# STM32U5A9 register map
File version: 1.7
CPU: CM33 r0p1, little endian, MPU, FPU, 4 interrupt priority bits
Registers are 32-bit, read-write, reset 0x0 unless marked. A register's access mark holds for its fields unless they carry their own. Offsets are from the block's base; [hi:lo] are bit positions; {n}, {i} and the like mark numbered series.

## DCMI — Digital camera interface
Base 0x4202C000
Same registers: SEC_DCMI 0x5202C000
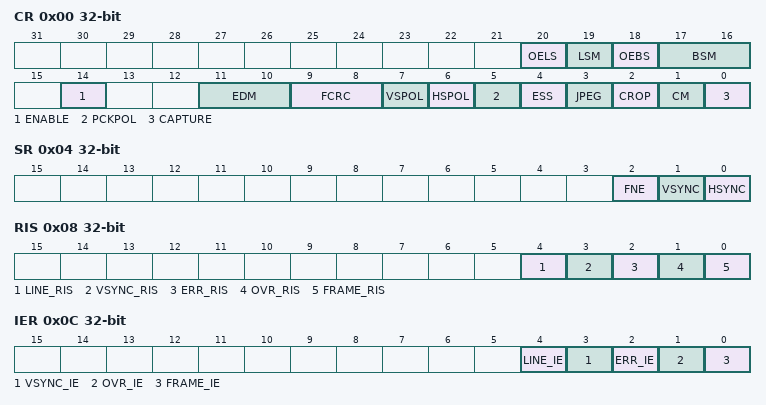
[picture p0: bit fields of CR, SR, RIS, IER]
0x00 CR — control register
  [20] OELS — Odd/Even Line Select (Line Select Start)
  [19] LSM — Line Select mode
  [18] OEBS — Odd/Even Byte Select (Byte Select Start)
  [17:16] BSM — Byte Select mode
  [14] ENABLE — DCMI enable
  [11:10] EDM — Extended data mode
  [9:8] FCRC — Frame capture rate control
  [7] VSPOL — Vertical synchronization polarity
  [6] HSPOL — Horizontal synchronization polarity
  [5] PCKPOL — Pixel clock polarity
  [4] ESS — Embedded synchronization select
  [3] JPEG — JPEG format
  [2] CROP — Crop feature
  [1] CM — Capture mode
  [0] CAPTURE — Capture enable
0x04 SR ro — status register
  [2] FNE — FIFO not empty
  [1] VSYNC — Vertical synchronization
  [0] HSYNC — Horizontal synchronization
0x08 RIS ro — raw interrupt status register
  [4] LINE_RIS — Line raw interrupt status
  [3] VSYNC_RIS — DCMI_VSYNC raw interrupt status
  [2] ERR_RIS — Synchronization error raw interrupt status
  [1] OVR_RIS — Overrun raw interrupt status
  [0] FRAME_RIS — Capture complete raw interrupt status
0x0C IER — interrupt enable register
  [4] LINE_IE — Line interrupt enable
  [3] VSYNC_IE — DCMI_VSYNC interrupt enable
  [2] ERR_IE — Synchronization error interrupt enable
  [1] OVR_IE — Overrun interrupt enable
  [0] FRAME_IE — Capture complete interrupt enable
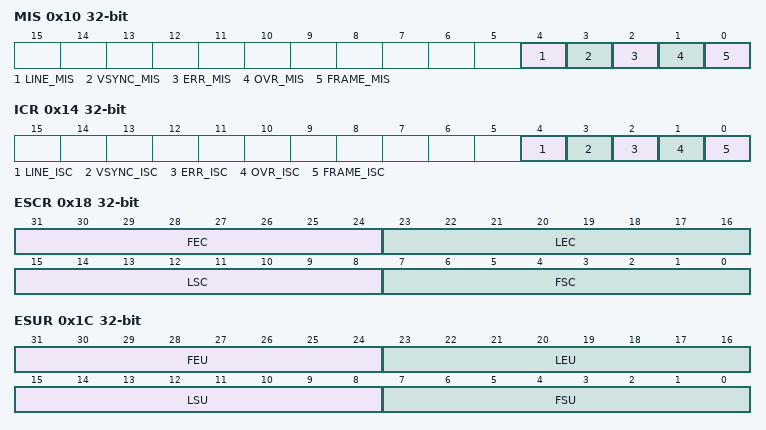
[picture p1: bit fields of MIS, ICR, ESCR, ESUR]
0x10 MIS ro — masked interrupt status register
  [4] LINE_MIS — Line masked interrupt status
  [3] VSYNC_MIS — VSYNC masked interrupt status
  [2] ERR_MIS — Synchronization error masked interrupt status
  [1] OVR_MIS — Overrun masked interrupt status
  [0] FRAME_MIS — Capture complete masked interrupt status
0x14 ICR wo — interrupt clear register
  [4] LINE_ISC — line interrupt status clear
  [3] VSYNC_ISC — Vertical Synchronization interrupt status clear
  [2] ERR_ISC — Synchronization error interrupt status clear
  [1] OVR_ISC — Overrun interrupt status clear
  [0] FRAME_ISC — Capture complete interrupt status clear
0x18 ESCR — background offset register
  [31:24] FEC — Frame end delimiter code
  [23:16] LEC — Line end delimiter code
  [15:8] LSC — Line start delimiter code
  [7:0] FSC — Frame start delimiter code
0x1C ESUR — embedded synchronization unmask register
  [31:24] FEU — Frame end delimiter unmask
  [23:16] LEU — Line end delimiter unmask
  [15:8] LSU — Line start delimiter unmask
  [7:0] FSU — Frame start delimiter unmask
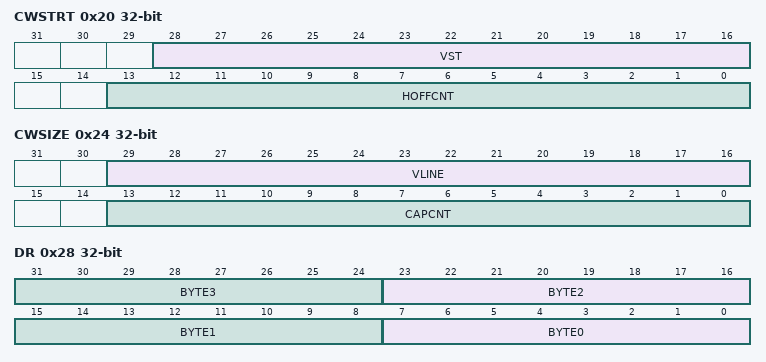
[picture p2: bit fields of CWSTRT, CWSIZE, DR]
0x20 CWSTRT — crop window start
  [28:16] VST — Vertical start line count
  [13:0] HOFFCNT — Horizontal offset count
0x24 CWSIZE — crop window size
  [29:16] VLINE — Vertical line count
  [13:0] CAPCNT — Capture count
0x28 DR ro — data register
  [8n+7:8n] BYTE{n} (n=0..3) — Data byte {n}

## DLYBOS1 — The delay block (DLYB) is used to generate an output clock that is dephased from the input clock
Base 0x420CF000
Same registers: DLYBSD1 0x420C8400, DLYBSD2 0x420C8800, DLYBOS2 0x420CF400, SEC_DLYBSD1 0x520C8400, SEC_DLYBSD2 0x520C8800, SEC_DLYBOS1 0x520CF000, SEC_DLYBOS2 0x520CF400
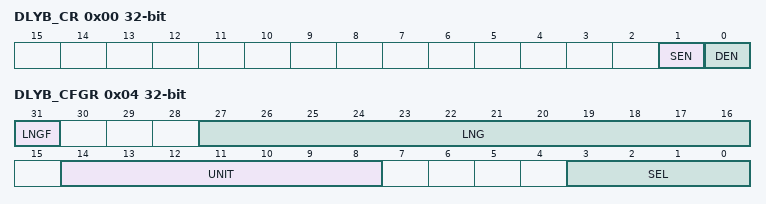
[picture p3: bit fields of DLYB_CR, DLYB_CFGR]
0x00 DLYB_CR — control register
  [1] SEN — OPALPM
  [0] DEN — Operational amplifier Enable
0x04 DLYB_CFGR access per field — configuration register
  [31] LNGF ro, [27:16] LNG ro, [14:8] UNIT rw, [3:0] SEL rw

## EXTI — External interrupt/event
Base 0x46022000
Same registers: SEC_EXTI 0x56022000
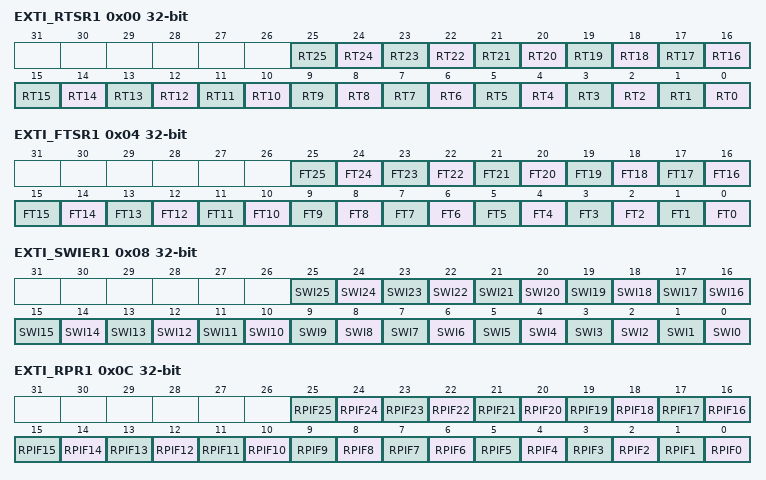
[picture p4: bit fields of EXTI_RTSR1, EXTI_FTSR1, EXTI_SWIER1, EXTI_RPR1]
0x00 EXTI_RTSR1 — EXTI rising trigger selection register
  [all] fields
    0=Rising trigger disabled (for event and interrupt) for input line; 1=Rising trigger enabled (for event and interrupt) for input line
  [n] RT{n} (n=0..25) — Rising trigger event configuration bit of configurable event input x
0x04 EXTI_FTSR1 — EXTI falling trigger selection register
  [all] fields
    0=Falling trigger disabled (for event and interrupt) for input line; 1=Falling trigger enabled (for event and interrupt) for input line
  [n] FT{n} (n=0..25) — Falling trigger event configuration bit of configurable event input x
0x08 EXTI_SWIER1 — EXTI software interrupt event register
  [all] fields
    0=Writing 0 has no effect; 1=Writing 1 triggers a rising edge event on event x. This bit is auto cleared by hardware.
  [n] SWI{n} (n=0..25) — Software interrupt on event x
0x0C EXTI_RPR1 — EXTI rising edge pending register
  [all] fields
    0=No rising edge trigger request occurred; 1=Rising edge trigger request occurred
  [n] RPIF{n} (n=0..25) — configurable event inputs x rising edge pending bit
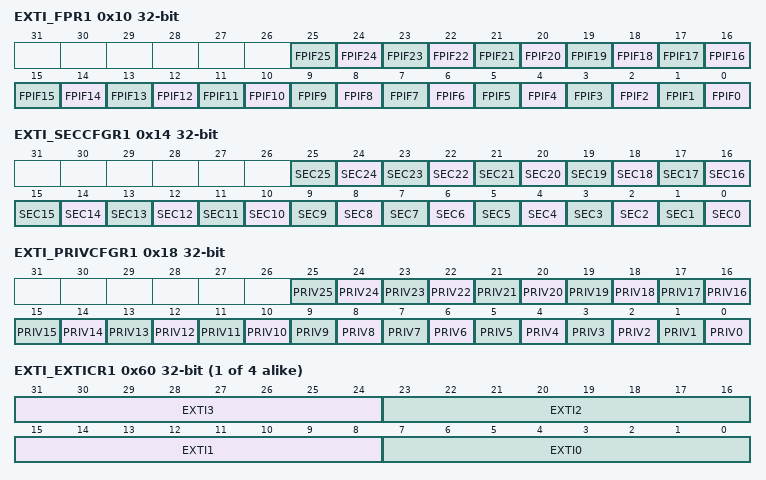
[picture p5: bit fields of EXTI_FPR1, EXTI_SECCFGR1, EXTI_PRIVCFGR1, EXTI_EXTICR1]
0x10 EXTI_FPR1 — EXTI falling edge pending register
  [all] fields
    0=No falling edge trigger request occurred; 1=Falling edge trigger request occurred
  [n] FPIF{n} (n=0..25) — configurable event inputs x falling edge pending bit
0x14 EXTI_SECCFGR1 — EXTI security configuration register
  [all] fields
    0=Event security disabled (non-secure); 1=Event security enabled (secure)
  [n] SEC{n} (n=0..25) — Security enable on event input x
0x18 EXTI_PRIVCFGR1 — EXTI privilege configuration register
  [all] fields
    0=Event privilege disabled (unprivileged); 1=Event privilege enabled (privileged)
  [n] PRIV{n} (n=0..25) — Security enable on event input x
{0x5C+4i} EXTI_EXTICR{i} (i=1..4) — EXTI external interrupt selection register
  [31:24] EXTI{4i-1} — EXTIm+3 GPIO port selection
  [23:16] EXTI{4i-2} — EXTIm+2 GPIO port selection
  [15:8] EXTI{4i-3} — EXTIm+1 GPIO port selection
  [7:0] EXTI{4i-4} — EXTIm GPIO port selection
0x70 EXTI_LOCKR — EXTI lock register
  [0] LOCK — Global security and privilege configuration registers (EXTI_SECCFGR and EXTI_PRIVCFGR) lock
    0=Security and privilege configuration open, can be modified; 1=Security and privilege configuration locked, can no longer be modified
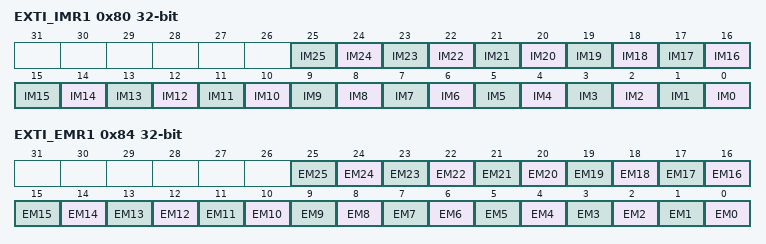
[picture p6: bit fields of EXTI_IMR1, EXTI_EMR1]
0x80 EXTI_IMR1 — EXTI CPU wake-up with interrupt mask register
  [all] fields
    0=Wake-up with interrupt request from input event x is masked; 1=Wake-up with interrupt request from input event x is unmasked
  [n] IM{n} (n=0..25) — CPU wake-up with interrupt mask on event input x
0x84 EXTI_EMR1 — EXTI CPU wake-up with event mask register
  [all] fields
    0=Wake-up with event generation from line x is masked; 1=Wake-up with event generation from line x is unmasked
  [n] EM{n} (n=0..25) — CPU wake-up with event generation mask on event input x

## Notices in the file
Copyright (c) 2025 STMicroelectronics.
SPDX-License-Identifier: Apache-2.0
Licensed under the Apache License, Version 2.0 (the "License");
you may not use this file except in compliance with the License.
You may obtain a copy of the License at
http://www.apache.org/licenses/LICENSE-2.0
Unless required by applicable law or agreed to in writing, software
distributed under the License is distributed on an "AS IS" BASIS,
WITHOUT WARRANTIES OR CONDITIONS OF ANY KIND, either express or implied.
See the License for the specific language governing permissions and
limitations under the License.
